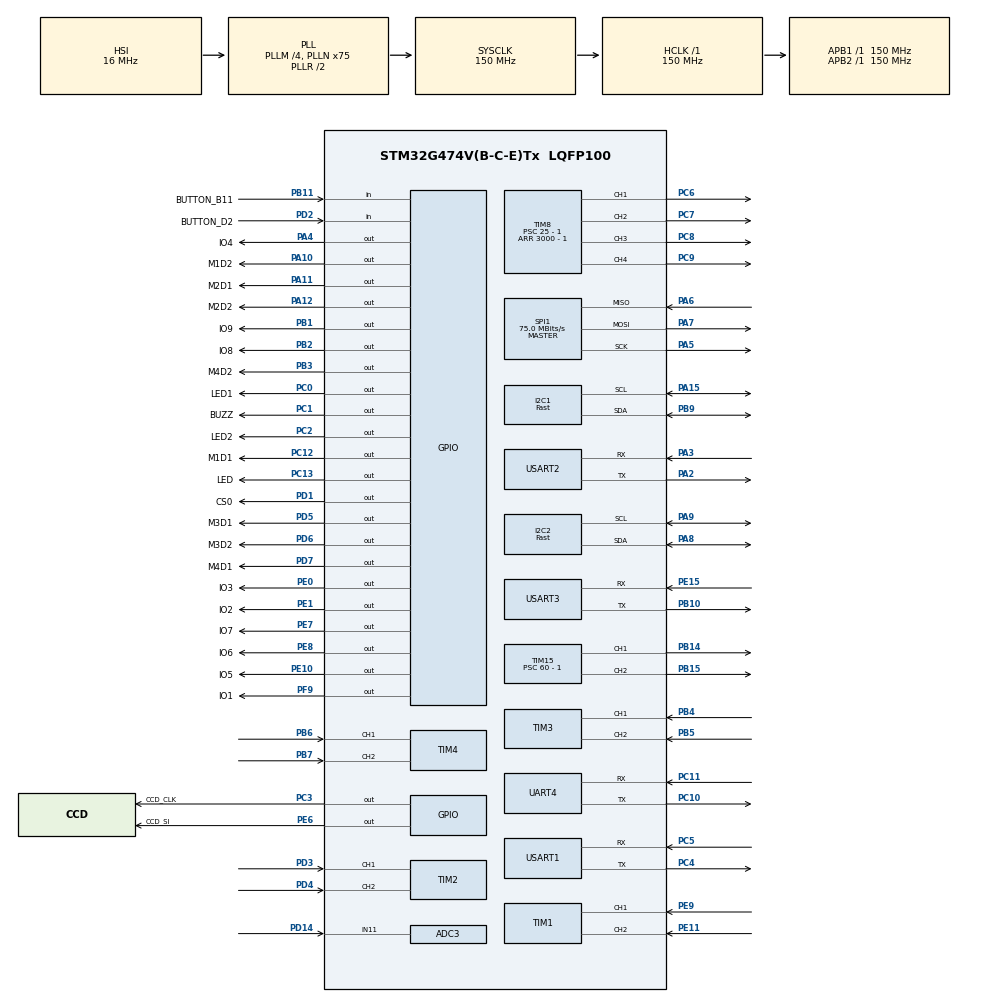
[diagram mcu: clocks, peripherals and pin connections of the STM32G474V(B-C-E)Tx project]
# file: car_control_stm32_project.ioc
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ADC3.Channel-0\#ChannelRegularConversion=ADC_CHANNEL_11
ADC3.NbrOfConversionFlag=1
ADC3.OffsetNumber-0\#ChannelRegularConversion=ADC_OFFSET_NONE
ADC3.Rank-0\#ChannelRegularConversion=1
ADC3.Resolution=ADC_RESOLUTION_8B
ADC3.SamplingTime-0\#ChannelRegularConversion=ADC_SAMPLETIME_2CYCLES_5
ADC3.master=1
Dma.ADC3.10.Direction=DMA_PERIPH_TO_MEMORY
Dma.ADC3.10.EventEnable=DISABLE
Dma.ADC3.10.Instance=DMA2_Channel5
Dma.ADC3.10.MemDataAlignment=DMA_MDATAALIGN_HALFWORD
Dma.ADC3.10.MemInc=DMA_MINC_ENABLE
Dma.ADC3.10.Mode=DMA_NORMAL
Dma.ADC3.10.PeriphDataAlignment=DMA_PDATAALIGN_HALFWORD
Dma.ADC3.10.PeriphInc=DMA_PINC_DISABLE
Dma.ADC3.10.Polarity=HAL_DMAMUX_REQ_GEN_RISING
Dma.ADC3.10.Priority=DMA_PRIORITY_LOW
Dma.ADC3.10.RequestNumber=1
Dma.ADC3.10.SignalID=NONE
Dma.ADC3.10.SyncEnable=DISABLE
Dma.ADC3.10.SyncPolarity=HAL_DMAMUX_SYNC_NO_EVENT
Dma.ADC3.10.SyncRequestNumber=1
Dma.ADC3.10.SyncSignalID=NONE
Dma.I2C1_RX.11.Direction=DMA_PERIPH_TO_MEMORY
Dma.I2C1_RX.11.EventEnable=DISABLE
Dma.I2C1_RX.11.Instance=DMA2_Channel1
Dma.I2C1_RX.11.MemDataAlignment=DMA_MDATAALIGN_BYTE
Dma.I2C1_RX.11.MemInc=DMA_MINC_ENABLE
Dma.I2C1_RX.11.Mode=DMA_NORMAL
Dma.I2C1_RX.11.PeriphDataAlignment=DMA_PDATAALIGN_BYTE
Dma.I2C1_RX.11.PeriphInc=DMA_PINC_DISABLE
Dma.I2C1_RX.11.Polarity=HAL_DMAMUX_REQ_GEN_RISING
Dma.I2C1_RX.11.Priority=DMA_PRIORITY_LOW
Dma.I2C1_RX.11.RequestNumber=1
Dma.I2C1_RX.11.SignalID=NONE
Dma.I2C1_RX.11.SyncEnable=DISABLE
Dma.I2C1_RX.11.SyncPolarity=HAL_DMAMUX_SYNC_NO_EVENT
Dma.I2C1_RX.11.SyncRequestNumber=1
Dma.I2C1_RX.11.SyncSignalID=NONE
Dma.I2C1_TX.12.Direction=DMA_MEMORY_TO_PERIPH
Dma.I2C1_TX.12.EventEnable=DISABLE
Dma.I2C1_TX.12.Instance=DMA2_Channel2
Dma.I2C1_TX.12.MemDataAlignment=DMA_MDATAALIGN_BYTE
Dma.I2C1_TX.12.MemInc=DMA_MINC_ENABLE
Dma.I2C1_TX.12.Mode=DMA_NORMAL
Dma.I2C1_TX.12.PeriphDataAlignment=DMA_PDATAALIGN_BYTE
Dma.I2C1_TX.12.PeriphInc=DMA_PINC_DISABLE
Dma.I2C1_TX.12.Polarity=HAL_DMAMUX_REQ_GEN_RISING
Dma.I2C1_TX.12.Priority=DMA_PRIORITY_LOW
Dma.I2C1_TX.12.RequestNumber=1
Dma.I2C1_TX.12.SignalID=NONE
Dma.I2C1_TX.12.SyncEnable=DISABLE
Dma.I2C1_TX.12.SyncPolarity=HAL_DMAMUX_SYNC_NO_EVENT
Dma.I2C1_TX.12.SyncRequestNumber=1
Dma.I2C1_TX.12.SyncSignalID=NONE
Dma.I2C2_RX.8.Direction=DMA_PERIPH_TO_MEMORY
Dma.I2C2_RX.8.EventEnable=DISABLE
Dma.I2C2_RX.8.Instance=DMA2_Channel3
Dma.I2C2_RX.8.MemDataAlignment=DMA_MDATAALIGN_BYTE
Dma.I2C2_RX.8.MemInc=DMA_MINC_ENABLE
Dma.I2C2_RX.8.Mode=DMA_NORMAL
Dma.I2C2_RX.8.PeriphDataAlignment=DMA_PDATAALIGN_BYTE
Dma.I2C2_RX.8.PeriphInc=DMA_PINC_DISABLE
Dma.I2C2_RX.8.Polarity=HAL_DMAMUX_REQ_GEN_RISING
Dma.I2C2_RX.8.Priority=DMA_PRIORITY_LOW
Dma.I2C2_RX.8.RequestNumber=1
Dma.I2C2_RX.8.SignalID=NONE
Dma.I2C2_RX.8.SyncEnable=DISABLE
Dma.I2C2_RX.8.SyncPolarity=HAL_DMAMUX_SYNC_NO_EVENT
Dma.I2C2_RX.8.SyncRequestNumber=1
Dma.I2C2_RX.8.SyncSignalID=NONE
Dma.I2C2_TX.9.Direction=DMA_MEMORY_TO_PERIPH
Dma.I2C2_TX.9.EventEnable=DISABLE
Dma.I2C2_TX.9.Instance=DMA2_Channel4
Dma.I2C2_TX.9.MemDataAlignment=DMA_MDATAALIGN_BYTE
Dma.I2C2_TX.9.MemInc=DMA_MINC_ENABLE
Dma.I2C2_TX.9.Mode=DMA_NORMAL
Dma.I2C2_TX.9.PeriphDataAlignment=DMA_PDATAALIGN_BYTE
Dma.I2C2_TX.9.PeriphInc=DMA_PINC_DISABLE
Dma.I2C2_TX.9.Polarity=HAL_DMAMUX_REQ_GEN_RISING
Dma.I2C2_TX.9.Priority=DMA_PRIORITY_LOW
Dma.I2C2_TX.9.RequestNumber=1
Dma.I2C2_TX.9.SignalID=NONE
Dma.I2C2_TX.9.SyncEnable=DISABLE
Dma.I2C2_TX.9.SyncPolarity=HAL_DMAMUX_SYNC_NO_EVENT
Dma.I2C2_TX.9.SyncRequestNumber=1
Dma.I2C2_TX.9.SyncSignalID=NONE
Dma.Request0=USART1_RX
Dma.Request1=USART1_TX
Dma.Request10=ADC3
Dma.Request11=I2C1_RX
Dma.Request12=I2C1_TX
Dma.Request2=USART2_RX
Dma.Request3=USART2_TX
Dma.Request4=USART3_RX
Dma.Request5=USART3_TX
Dma.Request6=UART4_RX
Dma.Request7=UART4_TX
Dma.Request8=I2C2_RX
Dma.Request9=I2C2_TX
Dma.UART4_RX.6.Direction=DMA_PERIPH_TO_MEMORY
Dma.UART4_RX.6.EventEnable=DISABLE
Dma.UART4_RX.6.Instance=DMA1_Channel7
Dma.UART4_RX.6.MemDataAlignment=DMA_MDATAALIGN_BYTE
Dma.UART4_RX.6.MemInc=DMA_MINC_ENABLE
Dma.UART4_RX.6.Mode=DMA_NORMAL
Dma.UART4_RX.6.PeriphDataAlignment=DMA_PDATAALIGN_BYTE
Dma.UART4_RX.6.PeriphInc=DMA_PINC_DISABLE
Dma.UART4_RX.6.Polarity=HAL_DMAMUX_REQ_GEN_RISING
Dma.UART4_RX.6.Priority=DMA_PRIORITY_LOW
Dma.UART4_RX.6.RequestNumber=1
Dma.UART4_RX.6.SignalID=NONE
Dma.UART4_RX.6.SyncEnable=DISABLE
Dma.UART4_RX.6.SyncPolarity=HAL_DMAMUX_SYNC_NO_EVENT
Dma.UART4_RX.6.SyncRequestNumber=1
Dma.UART4_RX.6.SyncSignalID=NONE
Dma.UART4_TX.7.Direction=DMA_MEMORY_TO_PERIPH
Dma.UART4_TX.7.EventEnable=DISABLE
Dma.UART4_TX.7.Instance=DMA1_Channel8
Dma.UART4_TX.7.MemDataAlignment=DMA_MDATAALIGN_BYTE
Dma.UART4_TX.7.MemInc=DMA_MINC_ENABLE
Dma.UART4_TX.7.Mode=DMA_NORMAL
Dma.UART4_TX.7.PeriphDataAlignment=DMA_PDATAALIGN_BYTE
Dma.UART4_TX.7.PeriphInc=DMA_PINC_DISABLE
Dma.UART4_TX.7.Polarity=HAL_DMAMUX_REQ_GEN_RISING
Dma.UART4_TX.7.Priority=DMA_PRIORITY_LOW
Dma.UART4_TX.7.RequestNumber=1
Dma.UART4_TX.7.SignalID=NONE
Dma.UART4_TX.7.SyncEnable=DISABLE
Dma.UART4_TX.7.SyncPolarity=HAL_DMAMUX_SYNC_NO_EVENT
Dma.UART4_TX.7.SyncRequestNumber=1
Dma.UART4_TX.7.SyncSignalID=NONE
Dma.USART1_RX.0.Direction=DMA_PERIPH_TO_MEMORY
Dma.USART1_RX.0.EventEnable=DISABLE
Dma.USART1_RX.0.Instance=DMA1_Channel1
Dma.USART1_RX.0.MemDataAlignment=DMA_MDATAALIGN_BYTE
Dma.USART1_RX.0.MemInc=DMA_MINC_ENABLE
Dma.USART1_RX.0.Mode=DMA_NORMAL
Dma.USART1_RX.0.PeriphDataAlignment=DMA_PDATAALIGN_BYTE
Dma.USART1_RX.0.PeriphInc=DMA_PINC_DISABLE
Dma.USART1_RX.0.Polarity=HAL_DMAMUX_REQ_GEN_RISING
Dma.USART1_RX.0.Priority=DMA_PRIORITY_LOW
Dma.USART1_RX.0.RequestNumber=1
Dma.USART1_RX.0.SignalID=NONE
Dma.USART1_RX.0.SyncEnable=DISABLE
Dma.USART1_RX.0.SyncPolarity=HAL_DMAMUX_SYNC_NO_EVENT
Dma.USART1_RX.0.SyncRequestNumber=1
Dma.USART1_RX.0.SyncSignalID=NONE
Dma.USART1_TX.1.Direction=DMA_MEMORY_TO_PERIPH
Dma.USART1_TX.1.EventEnable=DISABLE
Dma.USART1_TX.1.Instance=DMA1_Channel2
Dma.USART1_TX.1.MemDataAlignment=DMA_MDATAALIGN_BYTE
Dma.USART1_TX.1.MemInc=DMA_MINC_ENABLE
Dma.USART1_TX.1.Mode=DMA_NORMAL
Dma.USART1_TX.1.PeriphDataAlignment=DMA_PDATAALIGN_BYTE
Dma.USART1_TX.1.PeriphInc=DMA_PINC_DISABLE
Dma.USART1_TX.1.Polarity=HAL_DMAMUX_REQ_GEN_RISING
Dma.USART1_TX.1.Priority=DMA_PRIORITY_LOW
Dma.USART1_TX.1.RequestNumber=1
Dma.USART1_TX.1.SignalID=NONE
Dma.USART1_TX.1.SyncEnable=DISABLE
Dma.USART1_TX.1.SyncPolarity=HAL_DMAMUX_SYNC_NO_EVENT
Dma.USART1_TX.1.SyncRequestNumber=1
Dma.USART1_TX.1.SyncSignalID=NONE
Dma.USART2_RX.2.Direction=DMA_PERIPH_TO_MEMORY
Dma.USART2_RX.2.EventEnable=DISABLE
Dma.USART2_RX.2.Instance=DMA1_Channel3
Dma.USART2_RX.2.MemDataAlignment=DMA_MDATAALIGN_BYTE
Dma.USART2_RX.2.MemInc=DMA_MINC_ENABLE
Dma.USART2_RX.2.Mode=DMA_NORMAL
Dma.USART2_RX.2.PeriphDataAlignment=DMA_PDATAALIGN_BYTE
Dma.USART2_RX.2.PeriphInc=DMA_PINC_DISABLE
Dma.USART2_RX.2.Polarity=HAL_DMAMUX_REQ_GEN_RISING
Dma.USART2_RX.2.Priority=DMA_PRIORITY_LOW
Dma.USART2_RX.2.RequestNumber=1
Dma.USART2_RX.2.SignalID=NONE
Dma.USART2_RX.2.SyncEnable=DISABLE
Dma.USART2_RX.2.SyncPolarity=HAL_DMAMUX_SYNC_NO_EVENT
Dma.USART2_RX.2.SyncRequestNumber=1
Dma.USART2_RX.2.SyncSignalID=NONE
Dma.USART2_TX.3.Direction=DMA_MEMORY_TO_PERIPH
Dma.USART2_TX.3.EventEnable=DISABLE
Dma.USART2_TX.3.Instance=DMA1_Channel4
Dma.USART2_TX.3.MemDataAlignment=DMA_MDATAALIGN_BYTE
Dma.USART2_TX.3.MemInc=DMA_MINC_ENABLE
Dma.USART2_TX.3.Mode=DMA_NORMAL
Dma.USART2_TX.3.PeriphDataAlignment=DMA_PDATAALIGN_BYTE
Dma.USART2_TX.3.PeriphInc=DMA_PINC_DISABLE
Dma.USART2_TX.3.Polarity=HAL_DMAMUX_REQ_GEN_RISING
Dma.USART2_TX.3.Priority=DMA_PRIORITY_LOW
Dma.USART2_TX.3.RequestNumber=1
Dma.USART2_TX.3.SignalID=NONE
Dma.USART2_TX.3.SyncEnable=DISABLE
Dma.USART2_TX.3.SyncPolarity=HAL_DMAMUX_SYNC_NO_EVENT
Dma.USART2_TX.3.SyncRequestNumber=1
Dma.USART2_TX.3.SyncSignalID=NONE
Dma.USART3_RX.4.Direction=DMA_PERIPH_TO_MEMORY
Dma.USART3_RX.4.EventEnable=DISABLE
Dma.USART3_RX.4.Instance=DMA1_Channel5
Dma.USART3_RX.4.MemDataAlignment=DMA_MDATAALIGN_BYTE
Dma.USART3_RX.4.MemInc=DMA_MINC_ENABLE
Dma.USART3_RX.4.Mode=DMA_NORMAL
Dma.USART3_RX.4.PeriphDataAlignment=DMA_PDATAALIGN_BYTE
Dma.USART3_RX.4.PeriphInc=DMA_PINC_DISABLE
Dma.USART3_RX.4.Polarity=HAL_DMAMUX_REQ_GEN_RISING
Dma.USART3_RX.4.Priority=DMA_PRIORITY_LOW
Dma.USART3_RX.4.RequestNumber=1
Dma.USART3_RX.4.SignalID=NONE
Dma.USART3_RX.4.SyncEnable=DISABLE
Dma.USART3_RX.4.SyncPolarity=HAL_DMAMUX_SYNC_NO_EVENT
Dma.USART3_RX.4.SyncRequestNumber=1
Dma.USART3_RX.4.SyncSignalID=NONE
Dma.USART3_TX.5.Direction=DMA_MEMORY_TO_PERIPH
Dma.USART3_TX.5.EventEnable=DISABLE
Dma.USART3_TX.5.Instance=DMA1_Channel6
Dma.USART3_TX.5.MemDataAlignment=DMA_MDATAALIGN_BYTE
Dma.USART3_TX.5.MemInc=DMA_MINC_ENABLE
Dma.USART3_TX.5.Mode=DMA_NORMAL
Dma.USART3_TX.5.PeriphDataAlignment=DMA_PDATAALIGN_BYTE
Dma.USART3_TX.5.PeriphInc=DMA_PINC_DISABLE
Dma.USART3_TX.5.Polarity=HAL_DMAMUX_REQ_GEN_RISING
Dma.USART3_TX.5.Priority=DMA_PRIORITY_LOW
Dma.USART3_TX.5.RequestNumber=1
Dma.USART3_TX.5.SignalID=NONE
Dma.USART3_TX.5.SyncEnable=DISABLE
Dma.USART3_TX.5.SyncPolarity=HAL_DMAMUX_SYNC_NO_EVENT
Dma.USART3_TX.5.SyncRequestNumber=1
Dma.USART3_TX.5.SyncSignalID=NONE
I2C1.I2C_Speed_Mode=I2C_Fast
I2C1.Timing=0x00E063FF
I2C2.I2C_Speed_Mode=I2C_Fast
I2C2.Timing=0x00E063FF
Mcu.Family=STM32G4
Mcu.Name=STM32G474V(B-C-E)Tx
Mcu.Package=LQFP100
NVIC.DMA1_Channel1_IRQn=true\:0\:0\:false\:false\:true\:false\:true\:true
NVIC.DMA1_Channel2_IRQn=true\:0\:0\:false\:false\:true\:false\:true\:true
NVIC.DMA1_Channel3_IRQn=true\:0\:0\:false\:false\:true\:false\:true\:true
NVIC.DMA1_Channel4_IRQn=true\:0\:0\:false\:false\:true\:false\:true\:true
NVIC.DMA1_Channel5_IRQn=true\:0\:0\:false\:false\:true\:false\:true\:true
NVIC.DMA1_Channel6_IRQn=true\:0\:0\:false\:false\:true\:false\:true\:true
NVIC.DMA1_Channel7_IRQn=true\:0\:0\:false\:false\:true\:false\:true\:true
NVIC.DMA1_Channel8_IRQn=true\:0\:0\:false\:false\:true\:false\:true\:true
NVIC.DMA2_Channel1_IRQn=true\:0\:0\:false\:false\:true\:false\:true\:true
NVIC.DMA2_Channel2_IRQn=true\:0\:0\:false\:false\:true\:false\:true\:true
NVIC.DMA2_Channel3_IRQn=true\:0\:0\:false\:false\:true\:false\:true\:true
NVIC.DMA2_Channel4_IRQn=true\:0\:0\:false\:false\:true\:false\:true\:true
NVIC.DMA2_Channel5_IRQn=true\:0\:0\:false\:false\:true\:false\:true\:true
NVIC.I2C1_EV_IRQn=true\:0\:0\:false\:false\:true\:true\:true\:true
NVIC.PriorityGroup=NVIC_PRIORITYGROUP_4
NVIC.TIM1_TRG_COM_TIM17_IRQn=true\:15\:0\:false\:false\:true\:false\:true\:true
NVIC.TIM5_IRQn=true\:0\:0\:false\:false\:true\:true\:true\:true
NVIC.TIM6_DAC_IRQn=true\:0\:0\:false\:false\:true\:true\:true\:true
NVIC.UART4_IRQn=true\:0\:0\:false\:false\:true\:true\:true\:true
NVIC.USART1_IRQn=true\:0\:0\:false\:false\:true\:true\:true\:true
NVIC.USART2_IRQn=true\:0\:0\:false\:false\:true\:true\:true\:true
NVIC.USART3_IRQn=true\:0\:0\:false\:false\:true\:true\:true\:true
PA10.GPIO_Label=M1D2
PA10.Signal=GPIO_Output
PA11.GPIO_Label=M2D1
PA11.Signal=GPIO_Output
PA12.GPIO_Label=M2D2
PA12.Signal=GPIO_Output
PA13.Mode=Serial_Wire
PA13.Signal=SYS_JTMS-SWDIO
PA14.Mode=Serial_Wire
PA14.Signal=SYS_JTCK-SWCLK
PA15.Mode=I2C
PA15.Signal=I2C1_SCL
PA2.Mode=Asynchronous
PA2.Signal=USART2_TX
PA3.Mode=Asynchronous
PA3.Signal=USART2_RX
PA4.GPIO_Label=IO4
PA4.Signal=GPIO_Output
PA5.Mode=Full_Duplex_Master
PA5.Signal=SPI1_SCK
PA6.Mode=Full_Duplex_Master
PA6.Signal=SPI1_MISO
PA7.Mode=Full_Duplex_Master
PA7.Signal=SPI1_MOSI
PA8.Mode=I2C
PA8.Signal=I2C2_SDA
PA9.Mode=I2C
PA9.Signal=I2C2_SCL
PB1.GPIO_Label=IO9
PB1.Signal=GPIO_Output
PB10.Mode=Asynchronous
PB10.Signal=USART3_TX
PB11.GPIO_Label=BUTTON_B11
PB11.GPIO_PuPd=GPIO_PULLUP
PB11.Signal=GPIO_Input
PB14.Signal=S_TIM15_CH1
PB15.Signal=S_TIM15_CH2
PB2.GPIO_Label=IO8
PB2.Signal=GPIO_Output
PB3.GPIO_Label=M4D2
PB3.Signal=GPIO_Output
PB4.Signal=S_TIM3_CH1
PB5.Signal=S_TIM3_CH2
PB6.Signal=S_TIM4_CH1
PB7.Signal=S_TIM4_CH2
PB9.Mode=I2C
PB9.Signal=I2C1_SDA
PC0.GPIO_Label=LED1
PC0.Signal=GPIO_Output
PC1.GPIO_Label=BUZZ
PC1.Signal=GPIO_Output
PC10.Mode=Asynchronous
PC10.Signal=UART4_TX
PC11.Mode=Asynchronous
PC11.Signal=UART4_RX
PC12.GPIO_Label=M1D1
PC12.Signal=GPIO_Output
PC13.GPIO_Label=LED
PC13.Signal=GPIO_Output
PC2.GPIO_Label=LED2
PC2.Signal=GPIO_Output
PC3.GPIO_Label=CCD_CLK
PC3.Signal=GPIO_Output
PC4.Mode=Asynchronous
PC4.Signal=USART1_TX
PC5.Mode=Asynchronous
PC5.Signal=USART1_RX
PC6.Signal=S_TIM8_CH1
PC7.Signal=S_TIM8_CH2
PC8.Signal=S_TIM8_CH3
PC9.Signal=S_TIM8_CH4
PD1.GPIO_Label=CS0
PD1.Signal=GPIO_Output
PD14.Mode=IN11-Single-Ended
PD14.Signal=ADC3_IN11
PD2.GPIO_Label=BUTTON_D2
PD2.GPIO_PuPd=GPIO_PULLUP
PD2.Signal=GPIO_Input
PD3.Signal=S_TIM2_CH1
PD4.Signal=S_TIM2_CH2
PD5.GPIO_Label=M3D1
PD5.Signal=GPIO_Output
PD6.GPIO_Label=M3D2
PD6.Signal=GPIO_Output
PD7.GPIO_Label=M4D1
PD7.Signal=GPIO_Output
PE0.GPIO_Label=IO3
PE0.Signal=GPIO_Output
PE1.GPIO_Label=IO2
PE1.Signal=GPIO_Output
PE10.GPIO_Label=IO5
PE10.Signal=GPIO_Output
PE11.Signal=S_TIM1_CH2
PE15.Mode=Asynchronous
PE15.Signal=USART3_RX
PE2.Signal=SPI4_SCK
PE3.Signal=SPI4_NSS
PE5.Signal=SPI4_MISO
PE6.GPIO_Label=CCD_SI
PE6.Signal=GPIO_Output
PE7.GPIO_Label=IO7
PE7.Signal=GPIO_Output
PE8.GPIO_Label=IO6
PE8.Signal=GPIO_Output
PE9.Signal=S_TIM1_CH1
PF9.GPIO_Label=IO1
PF9.Signal=GPIO_Output
ProjectManager.HeapSize=0x200
ProjectManager.StackSize=0x400
ProjectManager.TargetToolchain=MDK-ARM V5.32
RCC.ADC12Freq_Value=150000000
RCC.ADC345Freq_Value=150000000
RCC.AHBFreq_Value=150000000
RCC.APB1Freq_Value=150000000
RCC.APB1TimFreq_Value=150000000
RCC.APB2Freq_Value=150000000
RCC.APB2TimFreq_Value=150000000
RCC.CortexFreq_Value=150000000
RCC.EXTERNAL_CLOCK_VALUE=12288000
RCC.HCLKFreq_Value=150000000
RCC.HSE_VALUE=8000000
RCC.HSI48_VALUE=48000000
RCC.HSI_VALUE=16000000
RCC.LSE_VALUE=32768
RCC.PLLM=RCC_PLLM_DIV4
RCC.PLLN=75
RCC.SYSCLKFreq_VALUE=150000000
RCC.SYSCLKSource=RCC_SYSCLKSOURCE_PLLCLK
RCC.USBFreq_Value=150000000
RCC.VCOOutputFreq_Value=300000000
SH.S_TIM15_CH1.0=TIM15_CH1,PWM Generation1 CH1
SH.S_TIM15_CH2.0=TIM15_CH2,PWM Generation2 CH2
SH.S_TIM1_CH1.0=TIM1_CH1,Encoder_Interface
SH.S_TIM1_CH2.0=TIM1_CH2,Encoder_Interface
SH.S_TIM2_CH1.0=TIM2_CH1,Encoder_Interface
SH.S_TIM2_CH2.0=TIM2_CH2,Encoder_Interface
SH.S_TIM3_CH1.0=TIM3_CH1,Encoder_Interface
SH.S_TIM3_CH2.0=TIM3_CH2,Encoder_Interface
SH.S_TIM4_CH1.0=TIM4_CH1,Encoder_Interface
SH.S_TIM4_CH2.0=TIM4_CH2,Encoder_Interface
SH.S_TIM8_CH1.0=TIM8_CH1,PWM Generation1 CH1
SH.S_TIM8_CH2.0=TIM8_CH2,PWM Generation2 CH2
SH.S_TIM8_CH3.0=TIM8_CH3,PWM Generation3 CH3
SH.S_TIM8_CH4.0=TIM8_CH4,PWM Generation4 CH4
SPI1.CalculateBaudRate=75.0 MBits/s
SPI1.Direction=SPI_DIRECTION_2LINES
SPI1.Mode=SPI_MODE_MASTER
SPI1.VirtualType=VM_MASTER
TIM1.EncoderMode=TIM_ENCODERMODE_TI12
TIM15.AutoReloadPreload=TIM_AUTORELOAD_PRELOAD_ENABLE
TIM15.Channel-PWM\ Generation1\ CH1=TIM_CHANNEL_1
TIM15.Channel-PWM\ Generation2\ CH2=TIM_CHANNEL_2
TIM15.PeriodNoDither=50000-1
TIM15.Prescaler=60 - 1
TIM15.PulseNoDither_1=0
TIM15.PulseNoDither_2=0
TIM2.EncoderMode=TIM_ENCODERMODE_TI12
TIM3.EncoderMode=TIM_ENCODERMODE_TI12
TIM4.EncoderMode=TIM_ENCODERMODE_TI12
TIM5.AutoReloadPreload=TIM_AUTORELOAD_PRELOAD_ENABLE
TIM5.PeriodNoDither=1000-1
TIM5.Prescaler=150-1
TIM6.AutoReloadPreload=TIM_AUTORELOAD_PRELOAD_ENABLE
TIM6.PeriodNoDither=250-1
TIM6.Prescaler=3-1
TIM8.AutoReloadPreload=TIM_AUTORELOAD_PRELOAD_ENABLE
TIM8.Channel-PWM\ Generation1\ CH1=TIM_CHANNEL_1
TIM8.Channel-PWM\ Generation2\ CH2=TIM_CHANNEL_2
TIM8.Channel-PWM\ Generation3\ CH3=TIM_CHANNEL_3
TIM8.Channel-PWM\ Generation4\ CH4=TIM_CHANNEL_4
TIM8.PeriodNoDither=3000 - 1
TIM8.Prescaler=25 - 1
USART1.VirtualMode-Asynchronous=VM_ASYNC
USART2.VirtualMode-Asynchronous=VM_ASYNC
USART3.VirtualMode-Asynchronous=VM_ASYNC
VP_SYS_VS_DBSignals.Mode=DisableDeadBatterySignals
VP_TIM15_VS_ClockSourceINT.Mode=Internal
VP_TIM5_VS_ClockSourceINT.Mode=Internal
VP_TIM6_VS_ClockSourceINT.Mode=Enable_Timer
board=custom

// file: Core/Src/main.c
/* USER CODE BEGIN Header */
/**
 ******************************************************************************
 * @file           : main.c
 * @brief          : Main program body
 ******************************************************************************
 * @attention
 *
 * Copyright (c) 2025 STMicroelectronics.
 * All rights reserved.
 *
 * This software is licensed under terms that can be found in the LICENSE file
 * in the root directory of this software component.
 * If no LICENSE file comes with this software, it is provided AS-IS.
 *
 ******************************************************************************
 */
/* USER CODE END Header */
#include "main.h"

#include "adc.h"
#include "dma.h"
#include "gpio.h"
#include "i2c.h"
#include "spi.h"
#include "tim.h"
#include "usart.h"

/* USER CODE BEGIN Includes */
#include "log.h"
#include "status.h"
#include "uart_it.h"
/* USER CODE END Includes */

void SystemClock_Config(void);

int main(void) {

  /* MCU Configuration--------------------------------------------------------*/

  /* Reset of all peripherals, Initializes the Flash interface and the Systick. */
  HAL_Init();

  /* Configure the system clock */
  SystemClock_Config();

  /* Initialize all configured peripherals */
  MX_GPIO_Init();
  MX_DMA_Init();
  MX_ADC3_Init();
  MX_I2C2_Init();
  MX_TIM1_Init();
  MX_TIM2_Init();
  MX_TIM3_Init();
  MX_TIM4_Init();
  MX_TIM8_Init();
  MX_TIM15_Init();
  MX_UART4_Init();
  MX_USART1_UART_Init();
  MX_USART2_UART_Init();
  MX_USART3_UART_Init();
  MX_TIM5_Init();
  MX_TIM6_Init();
  MX_I2C1_Init();
  MX_SPI1_Init();
  /* USER CODE BEGIN 2 */
  init_status(&status, 1);

  after_init_state();

  HAL_TIM_Base_Start_IT(&htim5);

  /* USER CODE END 2 */

  /* Infinite loop */
  while (1) {

  }
}

void SystemClock_Config(void) {
  RCC_OscInitTypeDef RCC_OscInitStruct = {0};
  RCC_ClkInitTypeDef RCC_ClkInitStruct = {0};

  /** Configure the main internal regulator output voltage
   */
  HAL_PWREx_ControlVoltageScaling(PWR_REGULATOR_VOLTAGE_SCALE1);

  /** Initializes the RCC Oscillators according to the specified parameters
   * in the RCC_OscInitTypeDef structure.
   */
  RCC_OscInitStruct.OscillatorType = RCC_OSCILLATORTYPE_HSI;
  RCC_OscInitStruct.HSIState = RCC_HSI_ON;
  RCC_OscInitStruct.HSICalibrationValue = RCC_HSICALIBRATION_DEFAULT;
  RCC_OscInitStruct.PLL.PLLState = RCC_PLL_ON;
  RCC_OscInitStruct.PLL.PLLSource = RCC_PLLSOURCE_HSI;
  RCC_OscInitStruct.PLL.PLLM = RCC_PLLM_DIV4;
  RCC_OscInitStruct.PLL.PLLN = 75;
  RCC_OscInitStruct.PLL.PLLP = RCC_PLLP_DIV2;
  RCC_OscInitStruct.PLL.PLLQ = RCC_PLLQ_DIV2;
  RCC_OscInitStruct.PLL.PLLR = RCC_PLLR_DIV2;
  if (HAL_RCC_OscConfig(&RCC_OscInitStruct) != HAL_OK) {
    Error_Handler();
  }

  /** Initializes the CPU, AHB and APB buses clocks
   */
  RCC_ClkInitStruct.ClockType = RCC_CLOCKTYPE_HCLK | RCC_CLOCKTYPE_SYSCLK | RCC_CLOCKTYPE_PCLK1 | RCC_CLOCKTYPE_PCLK2;
  RCC_ClkInitStruct.SYSCLKSource = RCC_SYSCLKSOURCE_PLLCLK;
  RCC_ClkInitStruct.AHBCLKDivider = RCC_SYSCLK_DIV1;
  RCC_ClkInitStruct.APB1CLKDivider = RCC_HCLK_DIV1;
  RCC_ClkInitStruct.APB2CLKDivider = RCC_HCLK_DIV1;

  if (HAL_RCC_ClockConfig(&RCC_ClkInitStruct, FLASH_LATENCY_4) != HAL_OK) {
    Error_Handler();
  }
}

void Error_Handler(void) {
  __disable_irq();
  while (1) {
  }
}
